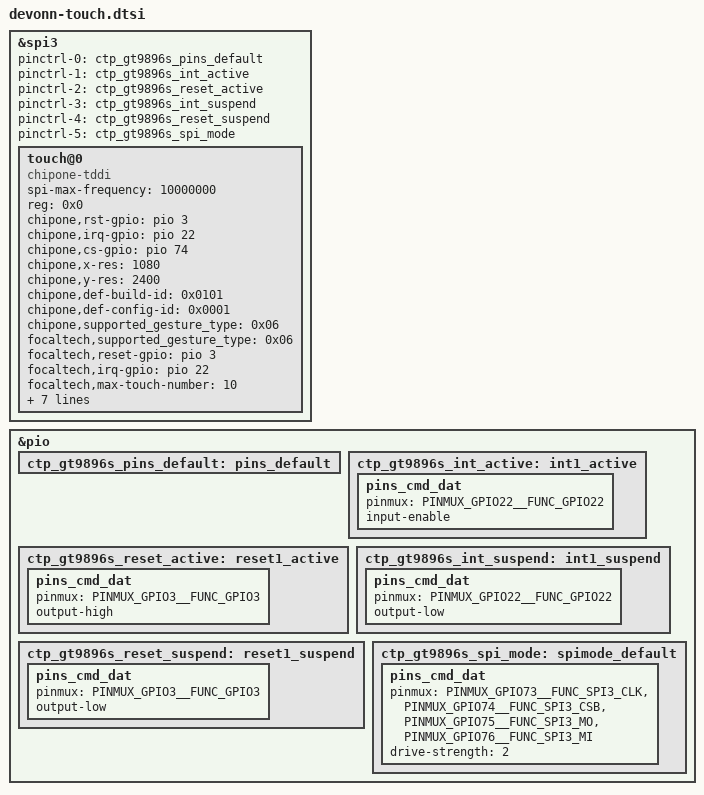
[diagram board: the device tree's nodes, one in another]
// SPDX-License-Identifier: (GPL-2.0 OR MIT)
/*
 * Copyright (C) 2020 MediaTek Inc.
 */

/* TOUCH start */

&spi3 {
	status = "okay";
	#address-cells = <1>;
	#size-cells = <0>;
	pinctrl-names = "default", "gt9896s_int_active",
		"gt9896s_reset_active", "gt9896s_int_suspend",
		"gt9896s_reset_suspend", "gt9896s_spi_mode";
	pinctrl-0 = <&ctp_gt9896s_pins_default>;
	pinctrl-1 = <&ctp_gt9896s_int_active>;
	pinctrl-2 = <&ctp_gt9896s_reset_active>;
	pinctrl-3 = <&ctp_gt9896s_int_suspend>;
	pinctrl-4 = <&ctp_gt9896s_reset_suspend>;
	pinctrl-5 = <&ctp_gt9896s_spi_mode>;

	touch@0{
		compatible = "chipone-tddi","focaltech,fts";
		spi-max-frequency = <10000000>;
		reg = <0x0>;
		status = "okay";

        chipone,rst-gpio = <&pio 3 0x0>;
        chipone,irq-gpio = <&pio 22 0x0>;
        chipone,cs-gpio = <&pio 74 0x0>;
        chipone,x-res = <1080>;
        chipone,y-res = <2400>;
        chipone,def-build-id = <0x0101>;
        chipone,def-config-id = <0x0001>;
	chipone,supported_gesture_type = <0x06>;
	focaltech,supported_gesture_type = <0x06>;
	focaltech,reset-gpio = <&pio 3 0x0>;
	focaltech,irq-gpio = <&pio 22 0x0>;
	focaltech,max-touch-number = <10>;
	focaltech,display-coords = <0 0 1080 2400>;
	focaltech,report_gesture_key = <59>;
	focaltech,panel-supplier = "txd","csot";
	focaltech,touch-charger-detect-psy-name = "battery";
	focaltech,touch-charger-detect-psp = "POWER_SUPPLY_PROP_STATUS";
	};
};

&pio {
	ctp_gt9896s_pins_default: pins_default {
	};
	ctp_gt9896s_int_active: int1_active {
		pins_cmd_dat {
			pinmux = <PINMUX_GPIO22__FUNC_GPIO22>;
			input-enable;
		};
	};
	ctp_gt9896s_reset_active: reset1_active {
		pins_cmd_dat {
			pinmux = <PINMUX_GPIO3__FUNC_GPIO3>;
			output-high;
		};
	};
	ctp_gt9896s_int_suspend: int1_suspend {
		pins_cmd_dat {
			pinmux = <PINMUX_GPIO22__FUNC_GPIO22>;
			output-low;
		};
	};
	ctp_gt9896s_reset_suspend: reset1_suspend {
		pins_cmd_dat {
			pinmux = <PINMUX_GPIO3__FUNC_GPIO3>;
			output-low;
		};
	};
	ctp_gt9896s_spi_mode: spimode_default {
		pins_cmd_dat {
			pinmux = <PINMUX_GPIO73__FUNC_SPI3_CLK>,
				<PINMUX_GPIO74__FUNC_SPI3_CSB>,
				<PINMUX_GPIO75__FUNC_SPI3_MO>,
				<PINMUX_GPIO76__FUNC_SPI3_MI>;
			drive-strength = <2>;
		};
	};
};
/* TOUCH end */
